BO_ 226 BMS_coulomb_counts: 8 Vector__XXX
	SG_ total_charge : 0|32@1- (1000,0) [0|0] "C" Vector__XXX
	SG_ total_discharge : 32|32@1- (1000,0) [0|0] "C" Vector__XXX

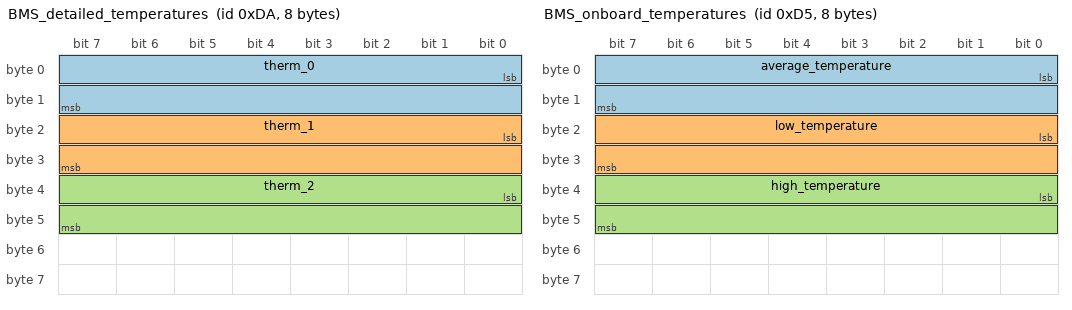
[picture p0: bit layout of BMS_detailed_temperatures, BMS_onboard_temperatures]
BO_ 218 BMS_detailed_temperatures: 8 Vector__XXX
	SG_ therm_0 : 0|16@1- (100,0) [0|0] "C" Vector__XXX
	SG_ therm_1 : 16|16@1- (100,0) [0|0] "C" Vector__XXX
	SG_ therm_2 : 32|16@1- (100,0) [0|0] "C" Vector__XXX

BO_ 214 BMS_onboard_detailed_temperature: 8 Vector__XXX
	SG_ temperature_0 : 0|16@1- (100,0) [0|0] "C" Vector__XXX
	SG_ temperature_1 : 16|16@1- (100,0) [0|0] "C" Vector__XXX

BO_ 213 BMS_onboard_temperatures: 8 Vector__XXX
	SG_ average_temperature : 0|16@1- (100,0) [0|0] "C" Vector__XXX
	SG_ low_temperature : 16|16@1- (100,0) [0|0] "C" Vector__XXX
	SG_ high_temperature : 32|16@1- (100,0) [0|0] "C" Vector__XXX

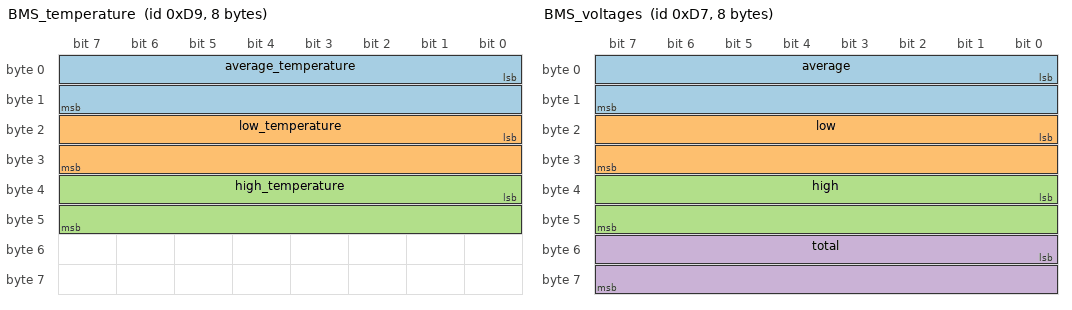
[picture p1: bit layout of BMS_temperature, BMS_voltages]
BO_ 217 BMS_temperature: 8 Vector__XXX
	SG_ average_temperature : 0|16@1- (100,0) [0|0] "C" Vector__XXX
	SG_ low_temperature : 16|16@1- (100,0) [0|0] "C" Vector__XXX
	SG_ high_temperature : 32|16@1- (100,0) [0|0] "C" Vector__XXX

BO_ 215 BMS_voltages: 8 Vector__XXX
	SG_ average : 0|16@1- (10000,0) [0|0] "V" Vector__XXX
	SG_ low : 16|16@1- (10000,0) [0|0] "V" Vector__XXX
	SG_ high : 32|16@1- (10000,0) [0|0] "V" Vector__XXX
	SG_ total : 48|16@1- (100,0) [0|0] "V" Vector__XXX

BO_ 1024 EM_measurement: 8 Vector__XXX
	SG_ voltage : 0|32@1- (65536,0) [0|0] "V" Vector__XXX
	SG_ current : 32|32@1- (65536,0) [0|0] "A" Vector__XXX

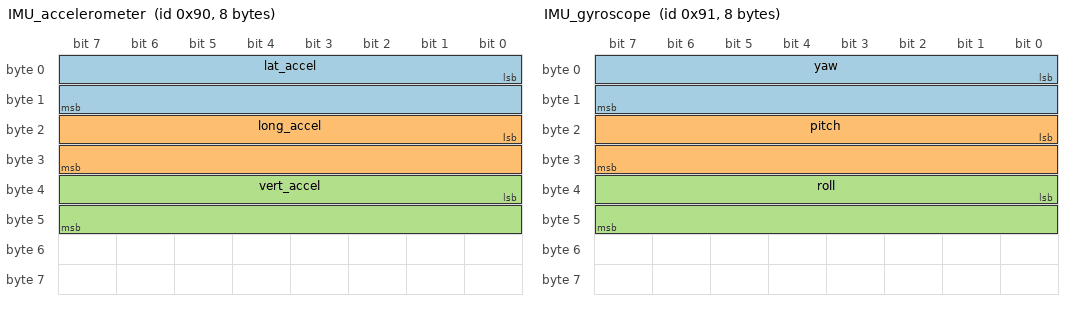
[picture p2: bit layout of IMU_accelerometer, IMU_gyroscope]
BO_ 144 IMU_accelerometer: 8 Vector__XXX
	SG_ lat_accel : 0|16@1- (102,0) [0|0] "m/s/s" Vector__XXX
	SG_ long_accel : 16|16@1- (102,0) [0|0] "m/s/s" Vector__XXX
	SG_ vert_accel : 32|16@1- (102,0) [0|0] "m/s/s" Vector__XXX

BO_ 145 IMU_gyroscope: 8 Vector__XXX
	SG_ yaw : 0|16@1- (3,0) [0|0] "DEG/S" Vector__XXX
	SG_ pitch : 16|16@1- (3,0) [0|0] "DEG/S" Vector__XXX
	SG_ roll : 32|16@1- (3,0) [0|0] "DEG/S" Vector__XXX

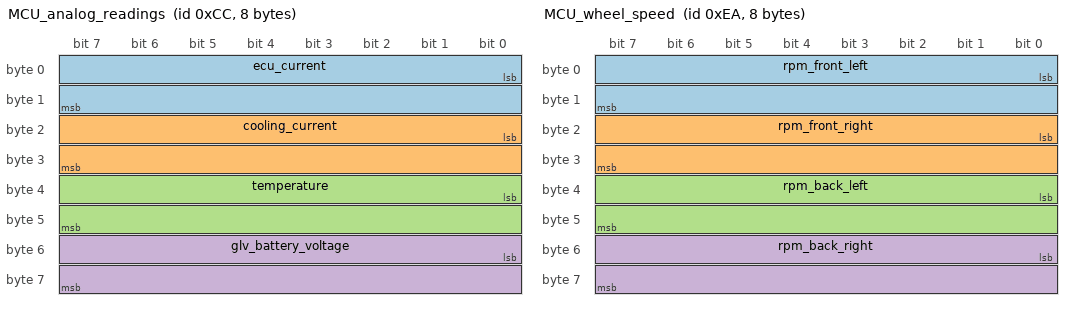
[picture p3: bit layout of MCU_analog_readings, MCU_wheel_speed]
BO_ 204 MCU_analog_readings: 8 Vector__XXX
	SG_ ecu_current : 0|16@1- (5000,0) [0|0] "A" Vector__XXX
	SG_ cooling_current : 16|16@1- (5000,0) [0|0] "A" Vector__XXX
	SG_ temperature : 32|16@1- (100,0) [0|0] "C" Vector__XXX
	SG_ glv_battery_voltage : 48|16@1- (2500,0) [0|0] "V" Vector__XXX

BO_ 231 MCU_GPS_readings: 8 Vector__XXX
	SG_ latitude : 0|32@1- (100000,0) [0|0] "DEG" Vector__XXX
	SG_ longitude : 32|32@1- (100000,0) [0|0] "DEG" Vector__XXX

BO_ 234 MCU_wheel_speed: 8 Vector__XXX
	SG_ rpm_front_left : 0|16@1- (10,0) [0|0] "rpm" Vector__XXX
	SG_ rpm_front_right : 16|16@1- (10,0) [0|0] "rpm" Vector__XXX
	SG_ rpm_back_left : 32|16@1- (10,0) [0|0] "rpm" Vector__XXX
	SG_ rpm_back_right : 48|16@1- (10,0) [0|0] "rpm" Vector__XXX

BO_ 146 SAB_readings_front: 8 Vector__XXX
	SG_ fl_susp_lin_pot : 0|16@1- (1000,0) [0|0] "mm" Vector__XXX
	SG_ fr_susp_lin_pot : 16|16@1- (1000,0) [0|0] "mm" Vector__XXX

BO_ 238 SAB_readings_gps: 8 Vector__XXX
	SG_ gps_latitude : 0|32@1- (1000000,0) [0|0] "DEG" Vector__XXX
	SG_ gps_longitude : 32|32@1- (1000000,0) [0|0] "DEG" Vector__XXX

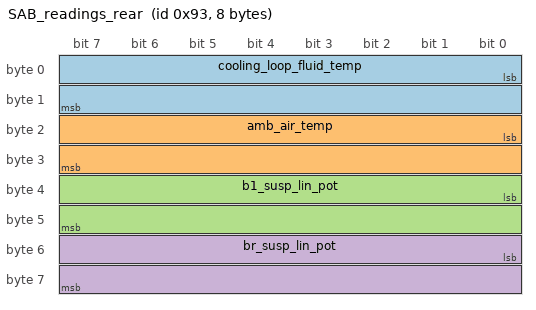
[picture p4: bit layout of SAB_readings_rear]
BO_ 147 SAB_readings_rear: 8 Vector__XXX
	SG_ cooling_loop_fluid_temp : 0|16@1- (1000,0) [0|0] "C" Vector__XXX
	SG_ amb_air_temp : 16|16@1- (1000,0) [0|0] "C" Vector__XXX
	SG_ b1_susp_lin_pot : 32|16@1- (1000,0) [0|0] "mm" Vector__XXX
	SG_ br_susp_lin_pot : 48|16@1- (1000,0) [0|0] "mm" Vector__XXX
